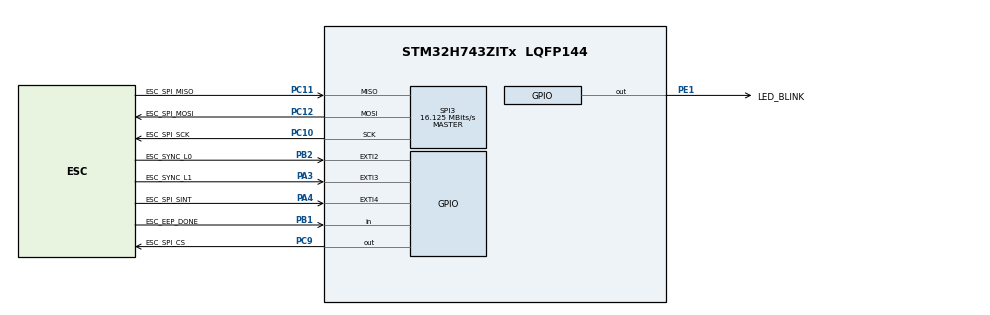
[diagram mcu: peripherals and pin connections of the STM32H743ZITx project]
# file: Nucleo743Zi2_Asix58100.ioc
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CORTEX_M7.default_mode_Activation=1
Mcu.Family=STM32H7
Mcu.Name=STM32H743ZITx
Mcu.Package=LQFP144
NVIC.EXTI2_IRQn=true\:0\:0\:false\:false\:true\:true\:true\:true
NVIC.EXTI3_IRQn=true\:0\:0\:false\:false\:true\:true\:true\:true
NVIC.EXTI4_IRQn=true\:0\:0\:false\:false\:true\:true\:true\:true
NVIC.PriorityGroup=NVIC_PRIORITYGROUP_4
NVIC.TIM16_IRQn=true\:0\:0\:false\:false\:true\:true\:true\:true
PA3.GPIO_Label=ESC_SYNC_L1
PA3.GPIO_ModeDefaultEXTI=GPIO_MODE_IT_FALLING
PA3.GPIO_PuPd=GPIO_PULLUP
PA3.Signal=GPXTI3
PA4.GPIO_Label=ESC_SPI_SINT
PA4.GPIO_ModeDefaultEXTI=GPIO_MODE_IT_FALLING
PA4.GPIO_PuPd=GPIO_PULLUP
PA4.Signal=GPXTI4
PB1.GPIO_Label=ESC_EEP_DONE
PB1.GPIO_PuPd=GPIO_PULLDOWN
PB1.Signal=GPIO_Input
PB2.GPIO_Label=ESC_SYNC_L0
PB2.GPIO_ModeDefaultEXTI=GPIO_MODE_IT_FALLING
PB2.GPIO_PuPd=GPIO_PULLUP
PB2.Signal=GPXTI2
PC10.GPIO_Label=ESC_SPI_SCK
PC10.GPIO_PuPd=GPIO_PULLUP
PC10.GPIO_Speed=GPIO_SPEED_FREQ_VERY_HIGH
PC10.Mode=Full_Duplex_Master
PC10.Signal=SPI3_SCK
PC11.GPIO_Label=ESC_SPI_MISO
PC11.GPIO_Speed=GPIO_SPEED_FREQ_VERY_HIGH
PC11.Mode=Full_Duplex_Master
PC11.Signal=SPI3_MISO
PC12.GPIO_Label=ESC_SPI_MOSI
PC12.GPIO_PuPd=GPIO_PULLUP
PC12.GPIO_Speed=GPIO_SPEED_FREQ_VERY_HIGH
PC12.Mode=Full_Duplex_Master
PC12.Signal=SPI3_MOSI
PC14-OSC32_IN\ (OSC32_IN).Mode=LSE-External-Oscillator
PC14-OSC32_IN\ (OSC32_IN).Signal=RCC_OSC32_IN
PC15-OSC32_OUT\ (OSC32_OUT).Mode=LSE-External-Oscillator
PC15-OSC32_OUT\ (OSC32_OUT).Signal=RCC_OSC32_OUT
PC9.GPIO_Label=ESC_SPI_CS
PC9.GPIO_PuPd=GPIO_PULLDOWN
PC9.GPIO_Speed=GPIO_SPEED_FREQ_VERY_HIGH
PC9.Signal=GPIO_Output
PE1.GPIO_Label=LED_BLINK
PE1.GPIO_PuPd=GPIO_PULLDOWN
PE1.Signal=GPIO_Output
PH0-OSC_IN\ (PH0).GPIO_Label=MCO
PH0-OSC_IN\ (PH0).Mode=HSE-External-Clock-Source
PH0-OSC_IN\ (PH0).Signal=RCC_OSC_IN
ProjectManager.HeapSize=0x200
ProjectManager.StackSize=0x400
ProjectManager.TargetToolchain=STM32CubeIDE
RCC.ADCFreq_Value=75000000
RCC.APB1Freq_Value=64000000
RCC.APB2Freq_Value=64000000
RCC.APB3Freq_Value=64000000
RCC.APB4Freq_Value=64000000
RCC.CortexFreq_Value=64000000
RCC.DIVN2=75
RCC.DIVQ2=3
RCC.HCLKFreq_Value=64000000
RCC.PWR_Regulator_Voltage_Scale=PWR_REGULATOR_VOLTAGE_SCALE1
RCC.SPI6CLockSelection=RCC_SPI6CLKSOURCE_PLL2
RCC.SYSCLKFreq_VALUE=64000000
RCC.USBFreq_Value=129000000
SPI3.BaudRatePrescaler=SPI_BAUDRATEPRESCALER_8
SPI3.CLKPhase=SPI_PHASE_2EDGE
SPI3.CLKPolarity=SPI_POLARITY_HIGH
SPI3.CalculateBaudRate=16.125 MBits/s
SPI3.DataSize=SPI_DATASIZE_8BIT
SPI3.Direction=SPI_DIRECTION_2LINES
SPI3.FifoThreshold=SPI_FIFO_THRESHOLD_04DATA
SPI3.Mode=SPI_MODE_MASTER
SPI3.NSSPMode=SPI_NSS_PULSE_DISABLE
SPI3.VirtualType=VM_MASTER
TIM16.Period=999
TIM16.Prescaler=63
TIM6.Period=999
TIM6.Prescaler=128-1
VP_MEMORYMAP_VS_MEMORYMAP.Mode=CurAppReg
VP_TIM16_VS_ClockSourceINT.Mode=Enable_Timer
VP_TIM6_VS_ClockSourceINT.Mode=Enable_Timer
board=custom

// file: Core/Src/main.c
/* USER CODE BEGIN Header */
/**
  ******************************************************************************
  * @file           : main.c
  * @brief          : Main program body
  ******************************************************************************
  * @attention
  *
  * Copyright (c) 2025 STMicroelectronics.
  * All rights reserved.
  *
  * This software is licensed under terms that can be found in the LICENSE file
  * in the root directory of this software component.
  * If no LICENSE file comes with this software, it is provided AS-IS.
  *
  ******************************************************************************
  */
/* USER CODE END Header */
#include "main.h"
#include "memorymap.h"
#include "spi.h"
#include "tim.h"
#include "gpio.h"

/* USER CODE BEGIN Includes */
//#include "Analog G0 - 8 Channel.h"
#include "Microcontroller_Asix58100_ESI.h"
/* USER CODE END Includes */

void SystemClock_Config(void);
static void MPU_Config(void);

/* USER CODE BEGIN 0 */
uint16_t data_in = 0;
void process_app(TOBJ7000 *OUT_GENERIC){
	data_in = OUT_GENERIC->OUT_GEN_INT1;
}
/* USER CODE END 0 */

int main(void)
{

  /* MPU Configuration--------------------------------------------------------*/
  MPU_Config();

  /* MCU Configuration--------------------------------------------------------*/

  /* Reset of all peripherals, Initializes the Flash interface and the Systick. */
  HAL_Init();

  /* Configure the system clock */
  SystemClock_Config();

  /* Initialize all configured peripherals */
  MX_GPIO_Init();
  MX_TIM6_Init();
  MX_TIM16_Init();
  MX_SPI3_Init();

  /* Infinite loop */
  while (1)
  {

    /* USER CODE BEGIN 3 */
	  // Get the timer period
	  HAL_GPIO_TogglePin(GPIOE, GPIO_PIN_1);
	  HAL_Delay(100);
	  main_initial();
  }
  /* USER CODE END 3 */
}

void SystemClock_Config(void)
{
  RCC_OscInitTypeDef RCC_OscInitStruct = {0};
  RCC_ClkInitTypeDef RCC_ClkInitStruct = {0};

  /** Supply configuration update enable
  */
  HAL_PWREx_ConfigSupply(PWR_LDO_SUPPLY);

  /** Configure the main internal regulator output voltage
  */
  __HAL_PWR_VOLTAGESCALING_CONFIG(PWR_REGULATOR_VOLTAGE_SCALE1);

  while(!__HAL_PWR_GET_FLAG(PWR_FLAG_VOSRDY)) {}

  /** Initializes the RCC Oscillators according to the specified parameters
  * in the RCC_OscInitTypeDef structure.
  */
  RCC_OscInitStruct.OscillatorType = RCC_OSCILLATORTYPE_HSI;
  RCC_OscInitStruct.HSIState = RCC_HSI_DIV1;
  RCC_OscInitStruct.HSICalibrationValue = RCC_HSICALIBRATION_DEFAULT;
  RCC_OscInitStruct.PLL.PLLState = RCC_PLL_ON;
  RCC_OscInitStruct.PLL.PLLSource = RCC_PLLSOURCE_HSI;
  RCC_OscInitStruct.PLL.PLLM = 32;
  RCC_OscInitStruct.PLL.PLLN = 129;
  RCC_OscInitStruct.PLL.PLLP = 2;
  RCC_OscInitStruct.PLL.PLLQ = 2;
  RCC_OscInitStruct.PLL.PLLR = 2;
  RCC_OscInitStruct.PLL.PLLRGE = RCC_PLL1VCIRANGE_1;
  RCC_OscInitStruct.PLL.PLLVCOSEL = RCC_PLL1VCOWIDE;
  RCC_OscInitStruct.PLL.PLLFRACN = 0;
  if (HAL_RCC_OscConfig(&RCC_OscInitStruct) != HAL_OK)
  {
    Error_Handler();
  }

  /** Initializes the CPU, AHB and APB buses clocks
  */
  RCC_ClkInitStruct.ClockType = RCC_CLOCKTYPE_HCLK|RCC_CLOCKTYPE_SYSCLK
                              |RCC_CLOCKTYPE_PCLK1|RCC_CLOCKTYPE_PCLK2
                              |RCC_CLOCKTYPE_D3PCLK1|RCC_CLOCKTYPE_D1PCLK1;
  RCC_ClkInitStruct.SYSCLKSource = RCC_SYSCLKSOURCE_HSI;
  RCC_ClkInitStruct.SYSCLKDivider = RCC_SYSCLK_DIV1;
  RCC_ClkInitStruct.AHBCLKDivider = RCC_HCLK_DIV1;
  RCC_ClkInitStruct.APB3CLKDivider = RCC_APB3_DIV1;
  RCC_ClkInitStruct.APB1CLKDivider = RCC_APB1_DIV1;
  RCC_ClkInitStruct.APB2CLKDivider = RCC_APB2_DIV1;
  RCC_ClkInitStruct.APB4CLKDivider = RCC_APB4_DIV1;

  if (HAL_RCC_ClockConfig(&RCC_ClkInitStruct, FLASH_LATENCY_0) != HAL_OK)
  {
    Error_Handler();
  }
}

 /* MPU Configuration */

void MPU_Config(void)
{
  MPU_Region_InitTypeDef MPU_InitStruct = {0};

  /* Disables the MPU */
  HAL_MPU_Disable();

  /** Initializes and configures the Region and the memory to be protected
  */
  MPU_InitStruct.Enable = MPU_REGION_ENABLE;
  MPU_InitStruct.Number = MPU_REGION_NUMBER0;
  MPU_InitStruct.BaseAddress = 0x0;
  MPU_InitStruct.Size = MPU_REGION_SIZE_4GB;
  MPU_InitStruct.SubRegionDisable = 0x87;
  MPU_InitStruct.TypeExtField = MPU_TEX_LEVEL0;
  MPU_InitStruct.AccessPermission = MPU_REGION_NO_ACCESS;
  MPU_InitStruct.DisableExec = MPU_INSTRUCTION_ACCESS_DISABLE;
  MPU_InitStruct.IsShareable = MPU_ACCESS_SHAREABLE;
  MPU_InitStruct.IsCacheable = MPU_ACCESS_NOT_CACHEABLE;
  MPU_InitStruct.IsBufferable = MPU_ACCESS_NOT_BUFFERABLE;

  HAL_MPU_ConfigRegion(&MPU_InitStruct);
  /* Enables the MPU */
  HAL_MPU_Enable(MPU_PRIVILEGED_DEFAULT);

}

void Error_Handler(void)
{
  __disable_irq();
  while (1)
  {
  }
}
